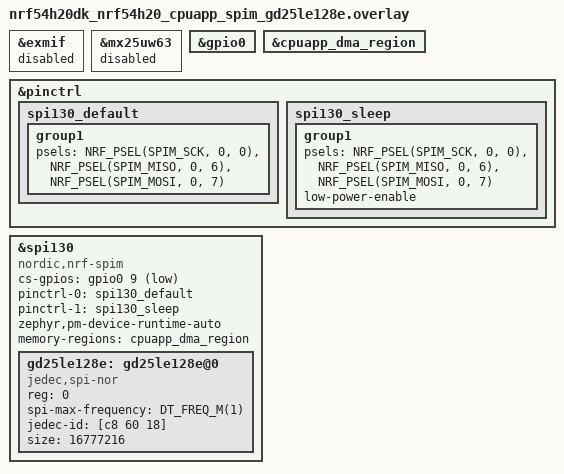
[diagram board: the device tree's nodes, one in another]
/*
 * Copyright (c) 2024 Nordic Semiconductor ASA
 *
 * SPDX-License-Identifier: Apache-2.0
 */

/* Disable EXMIF and Macronix flash */
&exmif {
	status = "disabled";
};

&mx25uw63 {
	status = "disabled";
};

/* Enable GPIO0 for CS pin */
&gpio0 {
	status = "okay";
};

&cpuapp_dma_region{
	status = "okay";
};

&pinctrl {
	spi130_default: spi130_default {
		group1 {
			psels = <NRF_PSEL(SPIM_SCK, 0, 0)>,
				<NRF_PSEL(SPIM_MISO, 0, 6)>,
				<NRF_PSEL(SPIM_MOSI, 0, 7)>;
		};
	};

	spi130_sleep: spi130_sleep {
		group1 {
			psels = <NRF_PSEL(SPIM_SCK, 0, 0)>,
				<NRF_PSEL(SPIM_MISO, 0, 6)>,
				<NRF_PSEL(SPIM_MOSI, 0, 7)>;
			low-power-enable;
		};
	};
};

/* Configure SPIM instance for GD25LE128E */
&spi130 {
	compatible = "nordic,nrf-spim";
	status = "okay";
	cs-gpios = <&gpio0 9 GPIO_ACTIVE_LOW>;
	pinctrl-0 = <&spi130_default>;
	pinctrl-1 = <&spi130_sleep>;
	zephyr,pm-device-runtime-auto;
	pinctrl-names = "default", "sleep";
	memory-regions = <&cpuapp_dma_region>;

	gd25le128e: gd25le128e@0 {
		compatible = "jedec,spi-nor";
		reg = <0>;
		spi-max-frequency = <DT_FREQ_M(1)>;
		jedec-id = [c8 60 18];
		size = <16777216>;
		status = "okay";
	};
};
